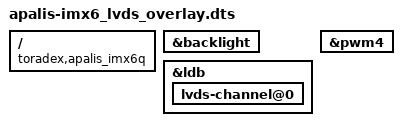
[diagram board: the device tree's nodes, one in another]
// SPDX-License-Identifier: GPL-2.0-or-later OR MIT
/*
 * Copyright 2020-2021 Toradex
 */

// Enable the LVDS interface on the Apalis iMX6Q. Make sure to also select a valid display configuration.

/dts-v1/;
/plugin/;

/ {
	compatible = "toradex,apalis_imx6q";
};

&backlight {
	status = "okay";
};

&ldb {
	#address-cells = <1>;
	#size-cells = <0>;

	status = "okay";

	lvds-channel@0 {
		status = "okay";
	};
};

&pwm4 {
	status = "okay";
};
